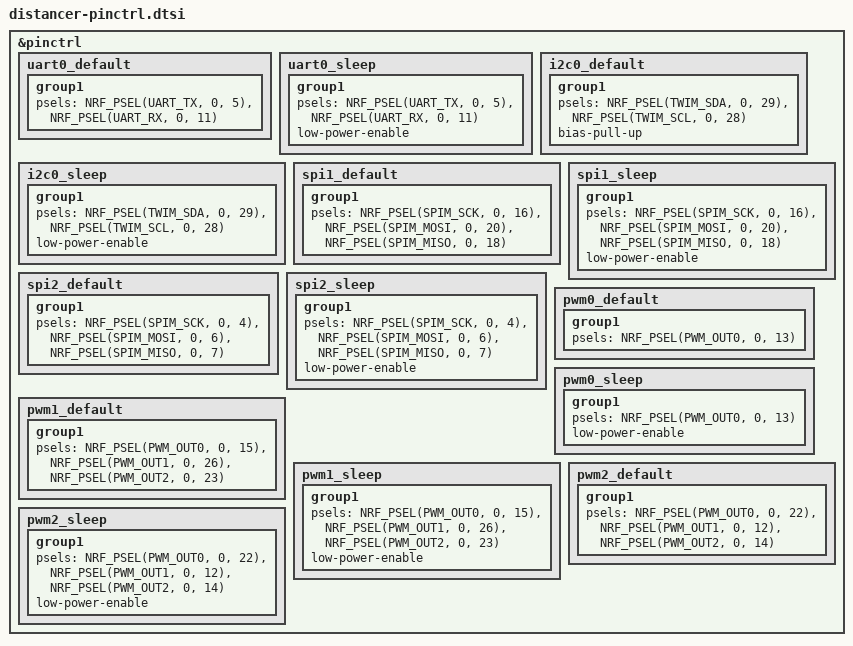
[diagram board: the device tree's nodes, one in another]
/*
 * Copyright (c) 2020 PHYTEC Messtechnik GmbH
 *
 * SPDX-License-Identifier: Apache-2.0
 *
 * Pin control groups for the distancer board. Translated from the legacy
 * "<peripheral>-pin" devicetree properties (Zephyr <= 2.x) to the pinctrl
 * model used by current Zephyr.
 */

&pinctrl {
	uart0_default: uart0_default {
		group1 {
			psels = <NRF_PSEL(UART_TX, 0, 5)>,
				<NRF_PSEL(UART_RX, 0, 11)>;
		};
	};

	uart0_sleep: uart0_sleep {
		group1 {
			psels = <NRF_PSEL(UART_TX, 0, 5)>,
				<NRF_PSEL(UART_RX, 0, 11)>;
			low-power-enable;
		};
	};

	i2c0_default: i2c0_default {
		group1 {
			psels = <NRF_PSEL(TWIM_SDA, 0, 29)>,
				<NRF_PSEL(TWIM_SCL, 0, 28)>;
			bias-pull-up;
		};
	};

	i2c0_sleep: i2c0_sleep {
		group1 {
			psels = <NRF_PSEL(TWIM_SDA, 0, 29)>,
				<NRF_PSEL(TWIM_SCL, 0, 28)>;
			low-power-enable;
		};
	};

	/* SPI1 -> DW1000 UWB transceiver */
	spi1_default: spi1_default {
		group1 {
			psels = <NRF_PSEL(SPIM_SCK, 0, 16)>,
				<NRF_PSEL(SPIM_MOSI, 0, 20)>,
				<NRF_PSEL(SPIM_MISO, 0, 18)>;
		};
	};

	spi1_sleep: spi1_sleep {
		group1 {
			psels = <NRF_PSEL(SPIM_SCK, 0, 16)>,
				<NRF_PSEL(SPIM_MOSI, 0, 20)>,
				<NRF_PSEL(SPIM_MISO, 0, 18)>;
			low-power-enable;
		};
	};

	/* SPI2 -> MX25R8035F external SPI-NOR flash */
	spi2_default: spi2_default {
		group1 {
			psels = <NRF_PSEL(SPIM_SCK, 0, 4)>,
				<NRF_PSEL(SPIM_MOSI, 0, 6)>,
				<NRF_PSEL(SPIM_MISO, 0, 7)>;
		};
	};

	spi2_sleep: spi2_sleep {
		group1 {
			psels = <NRF_PSEL(SPIM_SCK, 0, 4)>,
				<NRF_PSEL(SPIM_MOSI, 0, 6)>,
				<NRF_PSEL(SPIM_MISO, 0, 7)>;
			low-power-enable;
		};
	};

	/* PWM0 -> buzzer */
	pwm0_default: pwm0_default {
		group1 {
			psels = <NRF_PSEL(PWM_OUT0, 0, 13)>;
		};
	};

	pwm0_sleep: pwm0_sleep {
		group1 {
			psels = <NRF_PSEL(PWM_OUT0, 0, 13)>;
			low-power-enable;
		};
	};

	/* PWM1 -> RGB LED 1 (D23-D26) */
	pwm1_default: pwm1_default {
		group1 {
			psels = <NRF_PSEL(PWM_OUT0, 0, 15)>,
				<NRF_PSEL(PWM_OUT1, 0, 26)>,
				<NRF_PSEL(PWM_OUT2, 0, 23)>;
		};
	};

	pwm1_sleep: pwm1_sleep {
		group1 {
			psels = <NRF_PSEL(PWM_OUT0, 0, 15)>,
				<NRF_PSEL(PWM_OUT1, 0, 26)>,
				<NRF_PSEL(PWM_OUT2, 0, 23)>;
			low-power-enable;
		};
	};

	/* PWM2 -> RGB LED 2 (D3) */
	pwm2_default: pwm2_default {
		group1 {
			psels = <NRF_PSEL(PWM_OUT0, 0, 22)>,
				<NRF_PSEL(PWM_OUT1, 0, 12)>,
				<NRF_PSEL(PWM_OUT2, 0, 14)>;
		};
	};

	pwm2_sleep: pwm2_sleep {
		group1 {
			psels = <NRF_PSEL(PWM_OUT0, 0, 22)>,
				<NRF_PSEL(PWM_OUT1, 0, 12)>,
				<NRF_PSEL(PWM_OUT2, 0, 14)>;
			low-power-enable;
		};
	};
};
